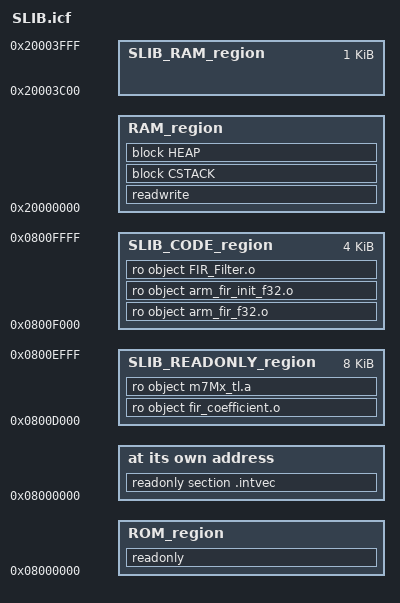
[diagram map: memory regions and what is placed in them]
/*###ICF### Section handled by ICF editor, don't touch! ****/
/*-Editor annotation file-*/
/* IcfEditorFile="$TOOLKIT_DIR$\config\ide\IcfEditor\cortex_v1_0.xml" */
/*-Specials-*/
define symbol __ICFEDIT_intvec_start__ = 0x08000000;
/*-Memory Regions-*/
define symbol __ICFEDIT_region_ROM_start__ = 0x08000000;
define symbol __ICFEDIT_region_ROM_end__   = 0x0800FFFF;

/* SLIB READ ONLY region */
define symbol __ICFEDIT_region_SLIB_READONLY_start__    = 0x0800D000;
define symbol __ICFEDIT_region_SLIB_READONLY_end__      = 0x0800EFFF;

/* SLIB CODE region */
define symbol __ICFEDIT_region_SLIB_CODE_start__    = 0x0800F000;
define symbol __ICFEDIT_region_SLIB_CODE_end__      = 0x0800FFFF;

/* SLIB used RAM region */
define symbol __ICFEDIT_region_SLIB_RAM_start__ = 0x20003C00;
define symbol __ICFEDIT_region_SLIB_RAM_end__   = 0x20003FFF;

/* RAM region */
define symbol __ICFEDIT_region_RAM_start__ = 0x20000000;
define symbol __ICFEDIT_region_RAM_end__   = 0x20003BFF;



/*-Sizes-*/
define symbol __ICFEDIT_size_cstack__ = 0x1000;
define symbol __ICFEDIT_size_heap__   = 0x1000;
/**** End of ICF editor section. ###ICF###*/

define memory mem with size = 4G;

/* Reserved 0x0800D000 ~ 0x0800FFF as sLib area */
define region ROM_region   = mem:[from __ICFEDIT_region_ROM_start__   to __ICFEDIT_region_ROM_end__]
                             -mem:[from __ICFEDIT_region_SLIB_READONLY_start__  to __ICFEDIT_region_SLIB_READONLY_end__] 
							               -mem:[from __ICFEDIT_region_SLIB_CODE_start__  to __ICFEDIT_region_SLIB_CODE_end__] ;

define region SLIB_READONLY_region   = mem:[from __ICFEDIT_region_SLIB_READONLY_start__   to __ICFEDIT_region_SLIB_READONLY_end__];

define region SLIB_CODE_region   = mem:[from __ICFEDIT_region_SLIB_CODE_start__   to __ICFEDIT_region_SLIB_CODE_end__];

/* Reserved 0x20003C00 ~ 0x20003FFF as RAM used for sLIB code */
define region RAM_region   = mem:[from __ICFEDIT_region_RAM_start__   to __ICFEDIT_region_RAM_end__]
                             - mem:[from __ICFEDIT_region_SLIB_RAM_start__   to __ICFEDIT_region_SLIB_RAM_end__];
                                           
define region SLIB_RAM_region = mem:[from __ICFEDIT_region_SLIB_RAM_start__   to __ICFEDIT_region_SLIB_RAM_end__];

define block CSTACK    with alignment = 8, size = __ICFEDIT_size_cstack__   { };
define block HEAP      with alignment = 8, size = __ICFEDIT_size_heap__     { };

initialize by copy { readwrite };
do not initialize  { section .noinit };

place at address mem:__ICFEDIT_intvec_start__ { readonly section .intvec };

place in ROM_region   { readonly };

/* Place SLIB protected data and software floating-point library into page sLib read-only region  */                              
place in SLIB_READONLY_region { ro object fir_coefficient.o,
                                ro object m7Mx_tl.a    /* m7Mx_tl.a is the software floating-point library with execute-only code */};       


/* Place IP Code into sLib code region */
place in SLIB_CODE_region   { ro object arm_fir_f32.o,
                              ro object arm_fir_init_f32.o,
                              ro object FIR_Filter.o,
                            }; 


place in RAM_region   { readwrite,
                        block CSTACK, block HEAP };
